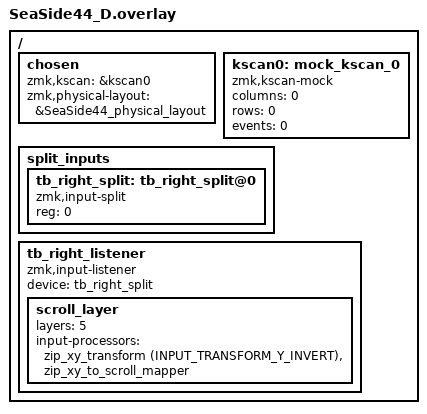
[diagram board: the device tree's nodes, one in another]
#include <physical_layouts.dtsi>
#include <input/processors.dtsi>
#include <dt-bindings/zmk/input_transform.h>
#include "SeaSide44.dtsi"

/ {
    chosen {
        zmk,kscan = &kscan0;
        zmk,physical-layout = &SeaSide44_physical_layout;
    };

    /* ドングルには物理キーがないため mock kscan を使う */
    kscan0: mock_kscan_0 {
        compatible = "zmk,kscan-mock";
        columns = <0>;
        rows = <0>;
        events = <0>;
    };

    /* 右トラックボールを split input として受信 */
    split_inputs {
        #address-cells = <1>;
        #size-cells = <0>;

        tb_right_split: tb_right_split@0 {
            compatible = "zmk,input-split";
            reg = <0>;
        };
    };

    /* ドングル側でトラックボール入力を処理 */
    tb_right_listener: tb_right_listener {
        compatible = "zmk,input-listener";
        status = "okay";
        device = <&tb_right_split>;
//        automouse-layer = <4>;
//        scroll-layers = <5>;

        scroll_layer {
            layers = <5>;
//            input-processors = <&zip_xy_to_scroll_mapper>;
            input-processors = <
                // 1. 正しくは &zip_xy_transform を使い、(INPUT_TRANSFORM_Y_INVERT) を渡します
                <&zip_xy_transform (INPUT_TRANSFORM_Y_INVERT)>,
                
                // 2. その後、スクロールに変換します
                <&zip_xy_to_scroll_mapper>
            >;
        };
    };
};
